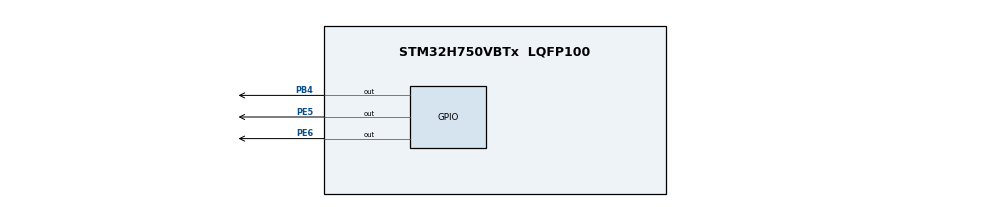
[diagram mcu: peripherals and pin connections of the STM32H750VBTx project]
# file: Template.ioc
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CORTEX_M7.CPU_DCache=Enabled
CORTEX_M7.CPU_ICache=Enabled
Mcu.Family=STM32H7
Mcu.Name=STM32H750VBTx
Mcu.Package=LQFP100
NVIC.PriorityGroup=NVIC_PRIORITYGROUP_4
PB4\ (NJTRST).GPIO_PuPd=GPIO_PULLUP
PB4\ (NJTRST).GPIO_Speed=GPIO_SPEED_FREQ_MEDIUM
PB4\ (NJTRST).PinState=GPIO_PIN_SET
PB4\ (NJTRST).Signal=GPIO_Output
PC14-OSC32_IN\ (OSC32_IN).Mode=LSE-External-Oscillator
PC14-OSC32_IN\ (OSC32_IN).Signal=RCC_OSC32_IN
PC15-OSC32_OUT\ (OSC32_OUT).Mode=LSE-External-Oscillator
PC15-OSC32_OUT\ (OSC32_OUT).Signal=RCC_OSC32_OUT
PE5.GPIO_PuPd=GPIO_PULLUP
PE5.GPIO_Speed=GPIO_SPEED_FREQ_MEDIUM
PE5.PinState=GPIO_PIN_SET
PE5.Signal=GPIO_Output
PE6.GPIO_PuPd=GPIO_PULLUP
PE6.GPIO_Speed=GPIO_SPEED_FREQ_MEDIUM
PE6.PinState=GPIO_PIN_SET
PE6.Signal=GPIO_Output
PH0-OSC_IN\ (PH0).Mode=HSE-External-Oscillator
PH0-OSC_IN\ (PH0).Signal=RCC_OSC_IN
PH1-OSC_OUT\ (PH1).Mode=HSE-External-Oscillator
PH1-OSC_OUT\ (PH1).Signal=RCC_OSC_OUT
ProjectManager.HeapSize=0x200
ProjectManager.StackSize=0x400
ProjectManager.TargetToolchain=MDK-ARM V5.27
RCC.ADCFreq_Value=16125000
RCC.APB1Freq_Value=120000000
RCC.APB2Freq_Value=120000000
RCC.APB3Freq_Value=120000000
RCC.APB4Freq_Value=120000000
RCC.CortexFreq_Value=480000000
RCC.D1PPRE=RCC_APB3_DIV2
RCC.D2PPRE1=RCC_APB1_DIV2
RCC.D2PPRE2=RCC_APB2_DIV2
RCC.D3PPRE=RCC_APB4_DIV2
RCC.DIVM1=2
RCC.DIVN1=240
RCC.HCLKFreq_Value=240000000
RCC.HPRE=RCC_HCLK_DIV2
RCC.HSE_VALUE=8000000
RCC.PLLSourceVirtual=RCC_PLLSOURCE_HSE
RCC.SYSCLKFreq_VALUE=480000000
RCC.SYSCLKSource=RCC_SYSCLKSOURCE_PLLCLK
RCC.USBFreq_Value=480000000
board=custom

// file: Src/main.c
/* USER CODE BEGIN Header */
/**
  ******************************************************************************
  * @file           : main.c
  * @brief          : Main program body
  ******************************************************************************
  * @attention
  *
  * <h2><center>&copy; Copyright (c) 2020 STMicroelectronics.
  * All rights reserved.</center></h2>
  *
  * This software component is licensed by ST under BSD 3-Clause license,
  * the "License"; You may not use this file except in compliance with the
  * License. You may obtain a copy of the License at:
  *                        opensource.org/licenses/BSD-3-Clause
  *
  ******************************************************************************
  */
/* USER CODE END Header */

#include "main.h"
#include "gpio.h"

void SystemClock_Config(void);

int main(void)
{

  /* Enable I-Cache---------------------------------------------------------*/
  SCB_EnableICache();

  /* Enable D-Cache---------------------------------------------------------*/
  SCB_EnableDCache();

  /* MCU Configuration--------------------------------------------------------*/

  /* Reset of all peripherals, Initializes the Flash interface and the Systick. */
  HAL_Init();

  /* Configure the system clock */
  SystemClock_Config();

  /* Initialize all configured peripherals */
  MX_GPIO_Init();

  /* Infinite loop */
  while (1)
  {

    /* USER CODE BEGIN 3 */
    HAL_GPIO_WritePin(GPIOB,GPIO_PIN_4,GPIO_PIN_SET);	/* PB4��1 */
    HAL_GPIO_WritePin(GPIOE,GPIO_PIN_5,GPIO_PIN_RESET);	/* PE5��0 */
    HAL_Delay(500);
    HAL_GPIO_WritePin(GPIOE,GPIO_PIN_5,GPIO_PIN_SET);	/* PE5��1 */
    HAL_GPIO_WritePin(GPIOE,GPIO_PIN_6,GPIO_PIN_RESET);	/* PE6��0 */
    HAL_Delay(500);
    HAL_GPIO_WritePin(GPIOE,GPIO_PIN_6,GPIO_PIN_SET);	/* PE6��1 */
    HAL_GPIO_WritePin(GPIOB,GPIO_PIN_4,GPIO_PIN_RESET);	/* PB4��0 */
    HAL_Delay(500);
  }
  /* USER CODE END 3 */
}

void SystemClock_Config(void)
{
  RCC_OscInitTypeDef RCC_OscInitStruct = {0};
  RCC_ClkInitTypeDef RCC_ClkInitStruct = {0};

  /** Supply configuration update enable
  */
  HAL_PWREx_ConfigSupply(PWR_LDO_SUPPLY);
  /** Configure the main internal regulator output voltage
  */
  __HAL_PWR_VOLTAGESCALING_CONFIG(PWR_REGULATOR_VOLTAGE_SCALE0);

  while(!__HAL_PWR_GET_FLAG(PWR_FLAG_VOSRDY)) {}
  /** Initializes the CPU, AHB and APB busses clocks
  */
  RCC_OscInitStruct.OscillatorType = RCC_OSCILLATORTYPE_HSE;
  RCC_OscInitStruct.HSEState = RCC_HSE_ON;
  RCC_OscInitStruct.PLL.PLLState = RCC_PLL_ON;
  RCC_OscInitStruct.PLL.PLLSource = RCC_PLLSOURCE_HSE;
  RCC_OscInitStruct.PLL.PLLM = 2;
  RCC_OscInitStruct.PLL.PLLN = 240;
  RCC_OscInitStruct.PLL.PLLP = 2;
  RCC_OscInitStruct.PLL.PLLQ = 2;
  RCC_OscInitStruct.PLL.PLLR = 2;
  RCC_OscInitStruct.PLL.PLLRGE = RCC_PLL1VCIRANGE_2;
  RCC_OscInitStruct.PLL.PLLVCOSEL = RCC_PLL1VCOWIDE;
  RCC_OscInitStruct.PLL.PLLFRACN = 0;
  if (HAL_RCC_OscConfig(&RCC_OscInitStruct) != HAL_OK)
  {
    Error_Handler();
  }
  /** Initializes the CPU, AHB and APB busses clocks
  */
  RCC_ClkInitStruct.ClockType = RCC_CLOCKTYPE_HCLK|RCC_CLOCKTYPE_SYSCLK
                              |RCC_CLOCKTYPE_PCLK1|RCC_CLOCKTYPE_PCLK2
                              |RCC_CLOCKTYPE_D3PCLK1|RCC_CLOCKTYPE_D1PCLK1;
  RCC_ClkInitStruct.SYSCLKSource = RCC_SYSCLKSOURCE_PLLCLK;
  RCC_ClkInitStruct.SYSCLKDivider = RCC_SYSCLK_DIV1;
  RCC_ClkInitStruct.AHBCLKDivider = RCC_HCLK_DIV2;
  RCC_ClkInitStruct.APB3CLKDivider = RCC_APB3_DIV2;
  RCC_ClkInitStruct.APB1CLKDivider = RCC_APB1_DIV2;
  RCC_ClkInitStruct.APB2CLKDivider = RCC_APB2_DIV2;
  RCC_ClkInitStruct.APB4CLKDivider = RCC_APB4_DIV2;

  if (HAL_RCC_ClockConfig(&RCC_ClkInitStruct, FLASH_LATENCY_4) != HAL_OK)
  {
    Error_Handler();
  }
}

void Error_Handler(void)
{
}

/************************ (C) COPYRIGHT STMicroelectronics *****END OF FILE****/
